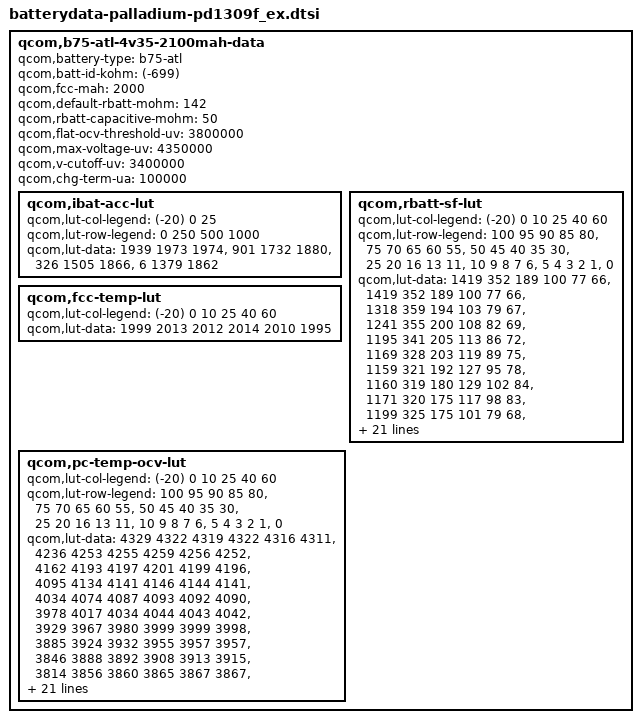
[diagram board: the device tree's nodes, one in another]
/* Copyright (c) 2013-2014, The Linux Foundation. All rights reserved.
 *
 * This program is free software; you can redistribute it and/or modify
 * it under the terms of the GNU General Public License version 2 and
 * only version 2 as published by the Free Software Foundation.
 *
 * This program is distributed in the hope that it will be useful,
 * but WITHOUT ANY WARRANTY; without even the implied warranty of
 * MERCHANTABILITY or FITNESS FOR A PARTICULAR PURPOSE.  See the
 * GNU General Public License for more details.
 */

qcom,b75-atl-4v35-2100mah-data {
	qcom,battery-type = "b75-atl";
	qcom,batt-id-kohm = <(-699)>;
	qcom,fcc-mah = <2000>;
	qcom,default-rbatt-mohm = <142>;
	qcom,rbatt-capacitive-mohm = <50>;
	qcom,flat-ocv-threshold-uv = <3800000>;
	qcom,max-voltage-uv = <4350000>;
	qcom,v-cutoff-uv = <3400000>;
	qcom,chg-term-ua = <100000>;

	qcom,ibat-acc-lut {
		qcom,lut-col-legend = <(-20) 0 25>;
		qcom,lut-row-legend = <0 250 500 1000>;
		qcom,lut-data = <1939 1973 1974>,
				<901 1732 1880>,
				<326 1505 1866>,
				<6 1379 1862>;
	};
	qcom,rbatt-sf-lut {
		qcom,lut-col-legend = <(-20) 0 10 25 40 60>;
		qcom,lut-row-legend = <100 95 90 85 80>,
					<75 70 65 60 55>,
					<50 45 40 35 30>,
					<25 20 16 13 11>,
					<10 9 8 7 6>,
					<5 4 3 2 1>,
					<0>;
		qcom,lut-data = <1419 352 189 100 77 66>,
				<1419 352 189 100 77 66>,
				<1318 359 194 103 79 67>,
				<1241 355 200 108 82 69>,
				<1195 341 205 113 86 72>,
				<1169 328 203 119 89 75>,
				<1159 321 192 127 95 78>,
				<1160 319 180 129 102 84>,
				<1171 320 175 117 98 83>,
				<1199 325 175 101 79 68>,
				<1247 331 178 101 79 68>,
				<1309 339 182 104 82 71>,
				<1386 342 187 107 86 74>,
				<1474 349 193 110 88 78>,
				<1563 352 202 113 86 72>,
				<1664 379 210 112 82 69>,
				<1808 445 205 112 82 69>,
				<2209 539 211 110 81 69>,
				<2852 631 227 107 79 69>,
				<3845 761 269 113 83 71>,
				<4640 835 294 117 85 72>,
				<5435 909 320 122 88 74>,
				<6231 1048 354 127 90 75>,
				<9688 1431 448 135 90 76>,
				<15161 1815 543 143 91 75>,
				<20634 2226 637 152 91 75>,
				<34613 4452 1273 157 95 74>,
				<69226 8904 2380 162 100 82>,
				<106411 17808 4362 192 109 90>,
				<212823 35616 8723 320 151 112>,
				<212823 35686 8753 360 181 152>;//<425645 71231 17447 639 302 224>;
	};
	qcom,fcc-temp-lut {
		qcom,lut-col-legend = <(-20) 0 10 25 40 60>;
		qcom,lut-data = <1999 2013 2012 2014 2010 1995>;
	};

	qcom,pc-temp-ocv-lut {
		qcom,lut-col-legend = <(-20) 0 10 25 40 60>;
		qcom,lut-row-legend = <100 95 90 85 80>,
					<75 70 65 60 55>,
					<50 45 40 35 30>,
					<25 20 16 13 11>,
					<10 9 8 7 6>,
					<5 4 3 2 1>,
					<0>;
		qcom,lut-data = <4329 4322 4319 4322 4316 4311>,
				<4236 4253 4255 4259 4256 4252>,
				<4162 4193 4197 4201 4199 4196>,
				<4095 4134 4141 4146 4144 4141>,
				<4034 4074 4087 4093 4092 4090>,
				<3978 4017 4034 4044 4043 4042>,
				<3929 3967 3980 3999 3999 3998>,
				<3885 3924 3932 3955 3957 3957>,
				<3846 3888 3892 3908 3913 3915>,
				<3814 3856 3860 3865 3867 3867>,
				<3790 3827 3834 3837 3839 3839>,
				<3770 3802 3810 3815 3817 3818>,
				<3753 3779 3791 3796 3799 3799>,
				<3738 3760 3775 3782 3783 3783>,
				<3721 3739 3762 3769 3767 3759>,
				<3703 3722 3746 3754 3749 3737>,
				<3679 3710 3720 3732 3727 3713>,
				<3652 3701 3702 3709 3704 3692>,
				<3626 3692 3692 3689 3684 3676>,
				<3602 3681 3684 3684 3678 3667>,
				<3586 3674 3681 3682 3677 3666>,
				<3570 3667 3677 3680 3675 3664>,
				<3555 3658 3671 3676 3674 3662>,
				<3531 3639 3654 3665 3659 3651>,
				<3501 3620 3636 3654 3645 3625>,
				<3471 3599 3618 3644 3631 3598>,
				<3436 3556 3573 3591 3581 3573>,
				<3385 3509 3522 3536 3523 3496>,
				<3337 3434 3447 3456 3443 3423>,
				<3273 3305 3325 3336 3317 3299>,
				<3200 3300 3300 3300 3300 3255>;//<3206 3000 3000 3000 3000 3000>;
	};
};
